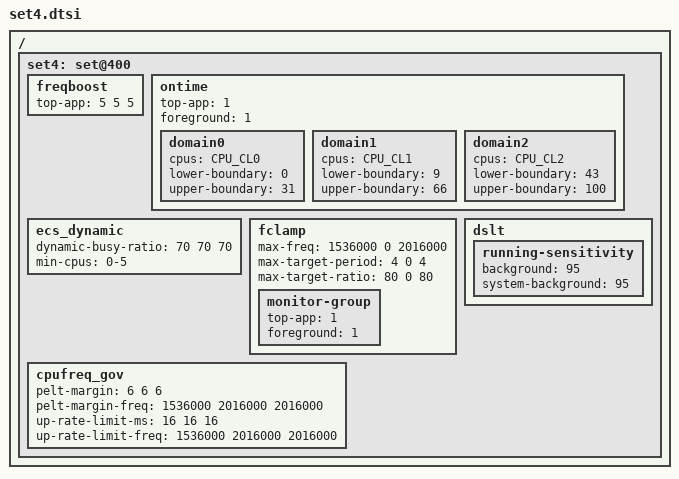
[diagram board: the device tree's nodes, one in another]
/ {
	/* balance mode - default */
	set4: set@400 {
		/* Boosting margin applied to frequency selection */
		freqboost {			/* LIT MID BIG */
			top-app			= <  5  5  5>;
		};

		/* Ontime Migration */
		ontime {
			top-app		= <1>;
			foreground	= <1>;

			domain0 {
				cpus = CPU_CL0;
				lower-boundary = <0>;
				upper-boundary = <31>;
			};
			domain1 {
				cpus = CPU_CL1;
				lower-boundary = <9>;
				upper-boundary = <66>;
			};
			domain2 {
				cpus = CPU_CL2;
				lower-boundary = <43>;
				upper-boundary = <100>;
			};
		};

		ecs_dynamic {
			dynamic-busy-ratio	= <70 70 70>;
			min-cpus = "0-5";
		};

		fclamp {
			max-freq          = < 1536000   0   2016000>;
			max-target-period = <       4   0         4>;
			max-target-ratio  = <      80   0        80>;

			monitor-group {
				top-app         = <1>;
				foreground      = <1>;
			};
		};

		cpufreq_gov {
				/* LITI MID BIG */
			pelt-margin = < 6 6 6  >;
			pelt-margin-freq = <1536000 2016000 2016000 >;
			up-rate-limit-ms = < 16 16 16 >;
			up-rate-limit-freq = <1536000 2016000 2016000 >;
		};		

		dslt {
			running-sensitivity {
				background = <95>;
				system-background = <95>;
			};
		};
	};
};
